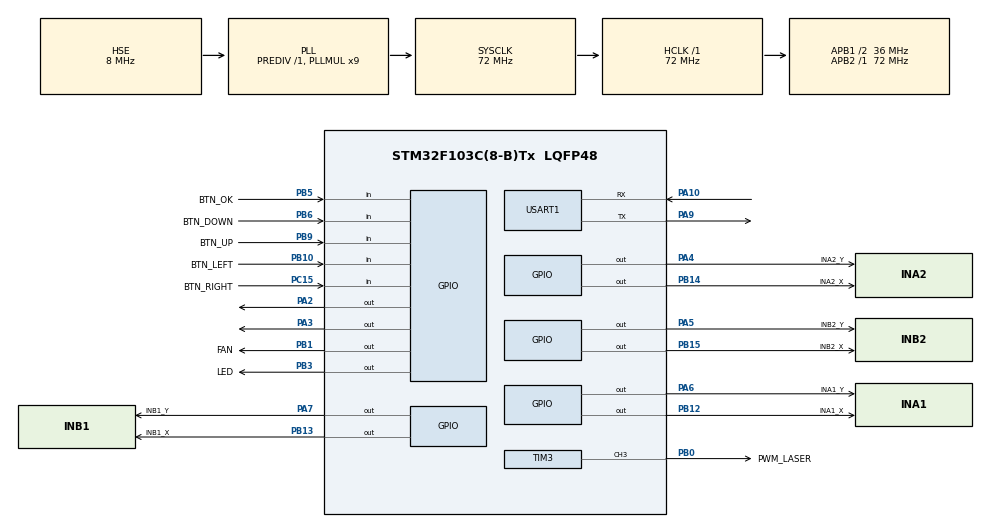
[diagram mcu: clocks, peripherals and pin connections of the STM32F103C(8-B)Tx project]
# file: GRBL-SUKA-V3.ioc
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Mcu.Family=STM32F1
Mcu.Name=STM32F103C(8-B)Tx
Mcu.Package=LQFP48
NVIC.PriorityGroup=NVIC_PRIORITYGROUP_4
NVIC.TIM2_IRQn=true\:0\:0\:false\:false\:true\:true
NVIC.TIM4_IRQn=true\:0\:0\:false\:false\:true\:true
NVIC.USART1_IRQn=true\:0\:0\:false\:false\:true\:true
PA10.Mode=Asynchronous
PA10.Signal=USART1_RX
PA13.Mode=Serial_Wire
PA13.Signal=SYS_JTMS-SWDIO
PA14.Mode=Serial_Wire
PA14.Signal=SYS_JTCK-SWCLK
PA2.Signal=GPIO_Output
PA3.Signal=GPIO_Output
PA4.GPIO_Label=INA2_Y
PA4.Signal=GPIO_Output
PA5.GPIO_Label=INB2_Y
PA5.Signal=GPIO_Output
PA6.GPIO_Label=INA1_Y
PA6.Signal=GPIO_Output
PA7.GPIO_Label=INB1_Y
PA7.Signal=GPIO_Output
PA9.Mode=Asynchronous
PA9.Signal=USART1_TX
PB0.GPIO_Label=PWM_LASER
PB0.Signal=S_TIM3_CH3
PB1.GPIO_Label=FAN
PB1.Signal=GPIO_Output
PB10.GPIO_Label=BTN_LEFT
PB10.GPIO_PuPd=GPIO_PULLUP
PB10.Signal=GPIO_Input
PB12.GPIO_Label=INA1_X
PB12.Signal=GPIO_Output
PB13.GPIO_Label=INB1_X
PB13.Signal=GPIO_Output
PB14.GPIO_Label=INA2_X
PB14.Signal=GPIO_Output
PB15.GPIO_Label=INB2_X
PB15.Signal=GPIO_Output
PB3.GPIO_Label=LED
PB3.Signal=GPIO_Output
PB5.GPIO_Label=BTN_OK
PB5.GPIO_PuPd=GPIO_PULLUP
PB5.Signal=GPIO_Input
PB6.GPIO_Label=BTN_DOWN
PB6.GPIO_PuPd=GPIO_PULLUP
PB6.Signal=GPIO_Input
PB9.GPIO_Label=BTN_UP
PB9.GPIO_PuPd=GPIO_PULLUP
PB9.Signal=GPIO_Input
PC15-OSC32_OUT.GPIO_Label=BTN_RIGHT
PC15-OSC32_OUT.GPIO_PuPd=GPIO_PULLUP
PC15-OSC32_OUT.Signal=GPIO_Input
PD0-OSC_IN.Mode=HSE-External-Oscillator
PD0-OSC_IN.Signal=RCC_OSC_IN
PD1-OSC_OUT.Mode=HSE-External-Oscillator
PD1-OSC_OUT.Signal=RCC_OSC_OUT
ProjectManager.HeapSize=0x200
ProjectManager.StackSize=0x400
ProjectManager.TargetToolchain=MDK-ARM V5
RCC.AHBFreq_Value=72000000
RCC.APB1CLKDivider=RCC_HCLK_DIV2
RCC.APB1Freq_Value=36000000
RCC.APB1TimFreq_Value=72000000
RCC.APB2Freq_Value=72000000
RCC.APB2TimFreq_Value=72000000
RCC.HCLKFreq_Value=72000000
RCC.PLLMUL=RCC_PLL_MUL9
RCC.PLLSourceVirtual=RCC_PLLSOURCE_HSE
RCC.SYSCLKFreq_VALUE=72000000
RCC.SYSCLKSource=RCC_SYSCLKSOURCE_PLLCLK
RCC.USBFreq_Value=48000000
RCC.USBPrescaler=RCC_USBCLKSOURCE_PLL_DIV1_5
SH.S_TIM3_CH3.0=TIM3_CH3,PWM Generation3 CH3
TIM2.Channel-Output\ Compare2\ No\ Output=TIM_CHANNEL_2
TIM3.Channel-PWM\ Generation3\ CH3=TIM_CHANNEL_3
TIM3.Period=35999
TIM3.Prescaler=1
TIM4.Channel-Output\ Compare2\ No\ Output=TIM_CHANNEL_2
USART1.VirtualMode=VM_ASYNC
VP_TIM2_VS_no_output2.Mode=Output Compare2 No Output
VP_TIM4_VS_no_output2.Mode=Output Compare2 No Output
board=custom

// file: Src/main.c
/**
  ******************************************************************************
  * @file           : main.c
  * @brief          : Main program body
  ******************************************************************************
  ** This notice applies to any and all portions of this file
  * that are not between comment pairs USER CODE BEGIN and
  * USER CODE END. Other portions of this file, whether
  * inserted by the user or by software development tools
  * are owned by their respective copyright owners.
  *
  * COPYRIGHT(c) 2018 STMicroelectronics
  *
  * Redistribution and use in source and binary forms, with or without modification,
  * are permitted provided that the following conditions are met:
  *   1. Redistributions of source code must retain the above copyright notice,
  *      this list of conditions and the following disclaimer.
  *   2. Redistributions in binary form must reproduce the above copyright notice,
  *      this list of conditions and the following disclaimer in the documentation
  *      and/or other materials provided with the distribution.
  *   3. Neither the name of STMicroelectronics nor the names of its contributors
  *      may be used to endorse or promote products derived from this software
  *      without specific prior written permission.
  *
  * THIS SOFTWARE IS PROVIDED BY THE COPYRIGHT HOLDERS AND CONTRIBUTORS "AS IS"
  * AND ANY EXPRESS OR IMPLIED WARRANTIES, INCLUDING, BUT NOT LIMITED TO, THE
  * IMPLIED WARRANTIES OF MERCHANTABILITY AND FITNESS FOR A PARTICULAR PURPOSE ARE
  * DISCLAIMED. IN NO EVENT SHALL THE COPYRIGHT HOLDER OR CONTRIBUTORS BE LIABLE
  * FOR ANY DIRECT, INDIRECT, INCIDENTAL, SPECIAL, EXEMPLARY, OR CONSEQUENTIAL
  * DAMAGES (INCLUDING, BUT NOT LIMITED TO, PROCUREMENT OF SUBSTITUTE GOODS OR
  * SERVICES; LOSS OF USE, DATA, OR PROFITS; OR BUSINESS INTERRUPTION) HOWEVER
  * CAUSED AND ON ANY THEORY OF LIABILITY, WHETHER IN CONTRACT, STRICT LIABILITY,
  * OR TORT (INCLUDING NEGLIGENCE OR OTHERWISE) ARISING IN ANY WAY OUT OF THE USE
  * OF THIS SOFTWARE, EVEN IF ADVISED OF THE POSSIBILITY OF SUCH DAMAGE.
  *
  ******************************************************************************
  */
#include "main.h"
#include "stm32f1xx_hal.h"

/* USER CODE BEGIN Includes */
#include "porting.h"
/* USER CODE END Includes */

TIM_HandleTypeDef htim2;
TIM_HandleTypeDef htim3;
TIM_HandleTypeDef htim4;

UART_HandleTypeDef huart1;

/* USER CODE BEGIN PV */
/* Private variables ---------------------------------------------------------*/

/* USER CODE END PV */

void SystemClock_Config(void);
static void MX_GPIO_Init(void);
static void MX_USART1_UART_Init(void);
static void MX_TIM3_Init(void);
static void MX_TIM4_Init(void);
static void MX_TIM2_Init(void);

void HAL_TIM_MspPostInit(TIM_HandleTypeDef *htim);

/* USER CODE BEGIN PFP */
/* Private function prototypes -----------------------------------------------*/

/* USER CODE END PFP */

int main(void)
{

  /* MCU Configuration----------------------------------------------------------*/

  /* Reset of all peripherals, Initializes the Flash interface and the Systick. */
  HAL_Init();

  /* Configure the system clock */
  SystemClock_Config();

  /* Initialize all configured peripherals */
  MX_GPIO_Init();
  MX_USART1_UART_Init();
  MX_TIM3_Init();
  MX_TIM4_Init();
  MX_TIM2_Init();
  /* USER CODE BEGIN 2 */
#if SUKA_V3
  grbl_main();
#endif
  /* USER CODE END 2 */

  /* Infinite loop */

}

void SystemClock_Config(void)
{

  RCC_OscInitTypeDef RCC_OscInitStruct;
  RCC_ClkInitTypeDef RCC_ClkInitStruct;

    /**Initializes the CPU, AHB and APB busses clocks
    */
  RCC_OscInitStruct.OscillatorType = RCC_OSCILLATORTYPE_HSE;
  RCC_OscInitStruct.HSEState = RCC_HSE_ON;
  RCC_OscInitStruct.HSEPredivValue = RCC_HSE_PREDIV_DIV1;
  RCC_OscInitStruct.HSIState = RCC_HSI_ON;
  RCC_OscInitStruct.PLL.PLLState = RCC_PLL_ON;
  RCC_OscInitStruct.PLL.PLLSource = RCC_PLLSOURCE_HSE;
  RCC_OscInitStruct.PLL.PLLMUL = RCC_PLL_MUL9;
  if (HAL_RCC_OscConfig(&RCC_OscInitStruct) != HAL_OK)
  {
    _Error_Handler(__FILE__, __LINE__);
  }

    /**Initializes the CPU, AHB and APB busses clocks
    */
  RCC_ClkInitStruct.ClockType = RCC_CLOCKTYPE_HCLK|RCC_CLOCKTYPE_SYSCLK
                              |RCC_CLOCKTYPE_PCLK1|RCC_CLOCKTYPE_PCLK2;
  RCC_ClkInitStruct.SYSCLKSource = RCC_SYSCLKSOURCE_PLLCLK;
  RCC_ClkInitStruct.AHBCLKDivider = RCC_SYSCLK_DIV1;
  RCC_ClkInitStruct.APB1CLKDivider = RCC_HCLK_DIV2;
  RCC_ClkInitStruct.APB2CLKDivider = RCC_HCLK_DIV1;

  if (HAL_RCC_ClockConfig(&RCC_ClkInitStruct, FLASH_LATENCY_2) != HAL_OK)
  {
    _Error_Handler(__FILE__, __LINE__);
  }

    /**Configure the Systick interrupt time
    */
  HAL_SYSTICK_Config(HAL_RCC_GetHCLKFreq()/1000);

    /**Configure the Systick
    */
  HAL_SYSTICK_CLKSourceConfig(SYSTICK_CLKSOURCE_HCLK);

  /* SysTick_IRQn interrupt configuration */
  HAL_NVIC_SetPriority(SysTick_IRQn, 0, 0);
}

/* TIM2 init function */
static void MX_TIM2_Init(void)
{

  TIM_MasterConfigTypeDef sMasterConfig;
  TIM_OC_InitTypeDef sConfigOC;

  htim2.Instance = TIM2;
  htim2.Init.Prescaler = 0;
  htim2.Init.CounterMode = TIM_COUNTERMODE_UP;
  htim2.Init.Period = 0;
  htim2.Init.ClockDivision = TIM_CLOCKDIVISION_DIV1;
  htim2.Init.AutoReloadPreload = TIM_AUTORELOAD_PRELOAD_DISABLE;
  if (HAL_TIM_OC_Init(&htim2) != HAL_OK)
  {
    _Error_Handler(__FILE__, __LINE__);
  }

  sMasterConfig.MasterOutputTrigger = TIM_TRGO_RESET;
  sMasterConfig.MasterSlaveMode = TIM_MASTERSLAVEMODE_DISABLE;
  if (HAL_TIMEx_MasterConfigSynchronization(&htim2, &sMasterConfig) != HAL_OK)
  {
    _Error_Handler(__FILE__, __LINE__);
  }

  sConfigOC.OCMode = TIM_OCMODE_TIMING;
  sConfigOC.Pulse = 0;
  sConfigOC.OCPolarity = TIM_OCPOLARITY_HIGH;
  sConfigOC.OCFastMode = TIM_OCFAST_DISABLE;
  if (HAL_TIM_OC_ConfigChannel(&htim2, &sConfigOC, TIM_CHANNEL_2) != HAL_OK)
  {
    _Error_Handler(__FILE__, __LINE__);
  }

}

/* TIM3 init function */
static void MX_TIM3_Init(void)
{

  TIM_MasterConfigTypeDef sMasterConfig;
  TIM_OC_InitTypeDef sConfigOC;

  htim3.Instance = TIM3;
  htim3.Init.Prescaler = 1;
  htim3.Init.CounterMode = TIM_COUNTERMODE_UP;
  htim3.Init.Period = 35999;
  htim3.Init.ClockDivision = TIM_CLOCKDIVISION_DIV1;
  htim3.Init.AutoReloadPreload = TIM_AUTORELOAD_PRELOAD_DISABLE;
  if (HAL_TIM_PWM_Init(&htim3) != HAL_OK)
  {
    _Error_Handler(__FILE__, __LINE__);
  }

  sMasterConfig.MasterOutputTrigger = TIM_TRGO_RESET;
  sMasterConfig.MasterSlaveMode = TIM_MASTERSLAVEMODE_DISABLE;
  if (HAL_TIMEx_MasterConfigSynchronization(&htim3, &sMasterConfig) != HAL_OK)
  {
    _Error_Handler(__FILE__, __LINE__);
  }

  sConfigOC.OCMode = TIM_OCMODE_PWM1;
  sConfigOC.Pulse = 0;
  sConfigOC.OCPolarity = TIM_OCPOLARITY_HIGH;
  sConfigOC.OCFastMode = TIM_OCFAST_DISABLE;
  if (HAL_TIM_PWM_ConfigChannel(&htim3, &sConfigOC, TIM_CHANNEL_3) != HAL_OK)
  {
    _Error_Handler(__FILE__, __LINE__);
  }

  HAL_TIM_MspPostInit(&htim3);

}

/* TIM4 init function */
static void MX_TIM4_Init(void)
{

  TIM_MasterConfigTypeDef sMasterConfig;
  TIM_OC_InitTypeDef sConfigOC;

  htim4.Instance = TIM4;
  htim4.Init.Prescaler = 0;
  htim4.Init.CounterMode = TIM_COUNTERMODE_UP;
  htim4.Init.Period = 0;
  htim4.Init.ClockDivision = TIM_CLOCKDIVISION_DIV1;
  htim4.Init.AutoReloadPreload = TIM_AUTORELOAD_PRELOAD_DISABLE;
  if (HAL_TIM_OC_Init(&htim4) != HAL_OK)
  {
    _Error_Handler(__FILE__, __LINE__);
  }

  sMasterConfig.MasterOutputTrigger = TIM_TRGO_RESET;
  sMasterConfig.MasterSlaveMode = TIM_MASTERSLAVEMODE_DISABLE;
  if (HAL_TIMEx_MasterConfigSynchronization(&htim4, &sMasterConfig) != HAL_OK)
  {
    _Error_Handler(__FILE__, __LINE__);
  }

  sConfigOC.OCMode = TIM_OCMODE_TIMING;
  sConfigOC.Pulse = 0;
  sConfigOC.OCPolarity = TIM_OCPOLARITY_HIGH;
  sConfigOC.OCFastMode = TIM_OCFAST_DISABLE;
  if (HAL_TIM_OC_ConfigChannel(&htim4, &sConfigOC, TIM_CHANNEL_2) != HAL_OK)
  {
    _Error_Handler(__FILE__, __LINE__);
  }

}

/* USART1 init function */
static void MX_USART1_UART_Init(void)
{

  huart1.Instance = USART1;
  huart1.Init.BaudRate = 115200;
  huart1.Init.WordLength = UART_WORDLENGTH_8B;
  huart1.Init.StopBits = UART_STOPBITS_1;
  huart1.Init.Parity = UART_PARITY_NONE;
  huart1.Init.Mode = UART_MODE_TX_RX;
  huart1.Init.HwFlowCtl = UART_HWCONTROL_NONE;
  huart1.Init.OverSampling = UART_OVERSAMPLING_16;
  if (HAL_UART_Init(&huart1) != HAL_OK)
  {
    _Error_Handler(__FILE__, __LINE__);
  }

}

/** Configure pins as
        * Analog
        * Input
        * Output
        * EVENT_OUT
        * EXTI
*/
static void MX_GPIO_Init(void)
{

  GPIO_InitTypeDef GPIO_InitStruct;

  /* GPIO Ports Clock Enable */
  __HAL_RCC_GPIOC_CLK_ENABLE();
  __HAL_RCC_GPIOD_CLK_ENABLE();
  __HAL_RCC_GPIOA_CLK_ENABLE();
  __HAL_RCC_GPIOB_CLK_ENABLE();

  /*Configure GPIO pin Output Level */
  HAL_GPIO_WritePin(GPIOA, GPIO_PIN_2|GPIO_PIN_3|INA2_Y_Pin|INB2_Y_Pin
                          |INA1_Y_Pin|INB1_Y_Pin, GPIO_PIN_RESET);

  /*Configure GPIO pin Output Level */
  HAL_GPIO_WritePin(GPIOB, FAN_Pin|INA1_X_Pin|INB1_X_Pin|INA2_X_Pin
                          |INB2_X_Pin|LED_Pin, GPIO_PIN_RESET);

  /*Configure GPIO pin : BTN_RIGHT_Pin */
  GPIO_InitStruct.Pin = BTN_RIGHT_Pin;
  GPIO_InitStruct.Mode = GPIO_MODE_INPUT;
  GPIO_InitStruct.Pull = GPIO_PULLUP;
  HAL_GPIO_Init(BTN_RIGHT_GPIO_Port, &GPIO_InitStruct);

  /*Configure GPIO pins : PA2 PA3 INA2_Y_Pin INB2_Y_Pin
                           INA1_Y_Pin INB1_Y_Pin */
  GPIO_InitStruct.Pin = GPIO_PIN_2|GPIO_PIN_3|INA2_Y_Pin|INB2_Y_Pin
                          |INA1_Y_Pin|INB1_Y_Pin;
  GPIO_InitStruct.Mode = GPIO_MODE_OUTPUT_PP;
  GPIO_InitStruct.Pull = GPIO_NOPULL;
  GPIO_InitStruct.Speed = GPIO_SPEED_FREQ_LOW;
  HAL_GPIO_Init(GPIOA, &GPIO_InitStruct);

  /*Configure GPIO pins : FAN_Pin INA1_X_Pin INB1_X_Pin INA2_X_Pin
                           INB2_X_Pin LED_Pin */
  GPIO_InitStruct.Pin = FAN_Pin|INA1_X_Pin|INB1_X_Pin|INA2_X_Pin
                          |INB2_X_Pin|LED_Pin;
  GPIO_InitStruct.Mode = GPIO_MODE_OUTPUT_PP;
  GPIO_InitStruct.Pull = GPIO_NOPULL;
  GPIO_InitStruct.Speed = GPIO_SPEED_FREQ_LOW;
  HAL_GPIO_Init(GPIOB, &GPIO_InitStruct);

  /*Configure GPIO pins : BTN_LEFT_Pin BTN_OK_Pin BTN_DOWN_Pin BTN_UP_Pin */
  GPIO_InitStruct.Pin = BTN_LEFT_Pin|BTN_OK_Pin|BTN_DOWN_Pin|BTN_UP_Pin;
  GPIO_InitStruct.Mode = GPIO_MODE_INPUT;
  GPIO_InitStruct.Pull = GPIO_PULLUP;
  HAL_GPIO_Init(GPIOB, &GPIO_InitStruct);

}

void _Error_Handler(char *file, int line)
{
  while(1)
  {
  }
}

/************************ (C) COPYRIGHT STMicroelectronics *****END OF FILE****/
